# GENET register map
File version: 5
BCM2711 GENET v5 Ethernet controller
Registers are read-write, no defined reset value unless marked. A register's access mark holds for its fields unless they carry their own. Offsets are from the block's base; lines under a group give offsets from that group; [hi:lo] are bit positions; {n}, {i} and the like mark numbered series; 'fields as' and 'values as' point back to an identical list; <NAME> marks a mode.

## Memory map
0x00000000 GENET size 0x10000

## GENET
Base 0x00000000
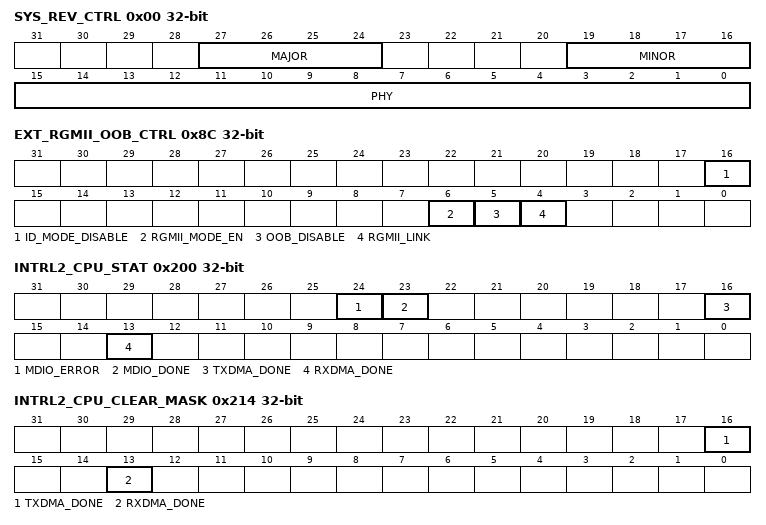
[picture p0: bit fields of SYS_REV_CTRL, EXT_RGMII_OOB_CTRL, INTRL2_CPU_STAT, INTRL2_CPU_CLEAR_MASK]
0x00 SYS_REV_CTRL ro — GENET_SYS_REV_CTRL (if_genetreg.h:38): the controller's revision; FreeBSD attaches major 6 only (if_genet.c:264-272)
  [27:24] MAJOR — Major revision, 6 for GENET v5 (if_genetreg.h:39, 41-43)
  [19:16] MINOR — Minor revision (if_genetreg.h:40, 44)
  [15:0] PHY — Internal PHY revision (if_genetreg.h:46)
0x04 SYS_PORT_CTRL — GENET_SYS_PORT_CTRL (if_genetreg.h:47)
  [31:0] MODE — Written whole: 3 for an external gigabit PHY over RGMII, 0 otherwise (if_genetreg.h:48; if_genet.c:915-925)
0x08 SYS_RBUF_FLUSH_CTRL — GENET_SYS_RBUF_FLUSH_CTRL (if_genetreg.h:49): FreeBSD pulses RESET and writes 0 (if_genet.c:492-501), and trusts UMAC_MAC0/1 only while it reads 0 (if_genet.c:465-468)
  [1] RESET — Flush the receive buffer (if_genetreg.h:50)
0x8C EXT_RGMII_OOB_CTRL — GENET_EXT_RGMII_OOB_CTRL (if_genetreg.h:52): set on link up (if_genet.c:1767-1775)
  [16] ID_MODE_DISABLE — Disable the MAC's internal delay (if_genetreg.h:53)
  [6] RGMII_MODE_EN — Enable RGMII (if_genetreg.h:54)
  [5] OOB_DISABLE — Disable out-of-band status (if_genetreg.h:55)
  [4] RGMII_LINK — The link is up (if_genetreg.h:56)
0x200 INTRL2_CPU_STAT ro — GENET_INTRL2_CPU_STAT (if_genetreg.h:57): pending interrupts, masked or not (if_genet.c:1354-1355)
  [24] MDIO_ERROR — An MDIO command failed (if_genetreg.h:62)
  [23] MDIO_DONE — An MDIO command finished (if_genetreg.h:63)
  [16] TXDMA_DONE — A transmit descriptor was sent (if_genetreg.h:64)
  [13] RXDMA_DONE — A receive descriptor was filled (if_genetreg.h:65)
0x208 INTRL2_CPU_CLEAR wo — GENET_INTRL2_CPU_CLEAR (if_genetreg.h:58): a 1 bit clears that pending interrupt (if_genet.c:1356)
  [31:0] IRQS — One bit per interrupt, STAT's bits
0x20C INTRL2_CPU_STAT_MASK ro — GENET_INTRL2_CPU_STAT_MASK (if_genetreg.h:59): the masked interrupts (if_genet.c:1355)
  [31:0] IRQS — One bit per interrupt, STAT's bits
0x210 INTRL2_CPU_SET_MASK wo — GENET_INTRL2_CPU_SET_MASK (if_genetreg.h:60): a 1 bit masks that interrupt; unverified, since FreeBSD writes all ones here and then to CLEAR_MASK to disable them (if_genet.c:544-545)
  [31:0] IRQS — One bit per interrupt, STAT's bits
0x214 INTRL2_CPU_CLEAR_MASK wo — GENET_INTRL2_CPU_CLEAR_MASK (if_genetreg.h:61): a 1 bit unmasks that interrupt (if_genet.c:536-537, 713-714); unverified, see SET_MASK. Its two named fields are the interrupts erx_genet unmasks, each one write
  [16] TXDMA_DONE write-1-clears — Unmasks STAT's TXDMA_DONE
  [13] RXDMA_DONE write-1-clears — Unmasks STAT's RXDMA_DONE
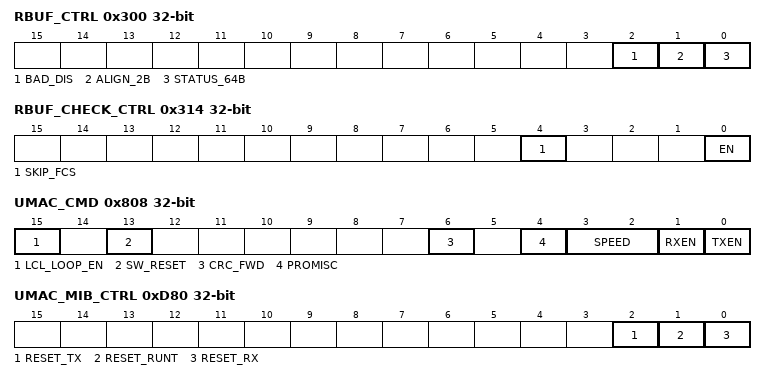
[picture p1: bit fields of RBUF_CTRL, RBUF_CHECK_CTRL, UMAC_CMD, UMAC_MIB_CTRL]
0x300 RBUF_CTRL — GENET_RBUF_CTRL (if_genetreg.h:66)
  [2] BAD_DIS — if_genetreg.h:67; FreeBSD never sets it
  [1] ALIGN_2B — Write two bytes of padding before each frame (if_genetreg.h:68; if_genet.c:522-524)
  [0] STATUS_64B — Prepend a 64-byte status block to each received frame (if_genetreg.h:69; if_genet.c:572-582)
0x314 RBUF_CHECK_CTRL — GENET_RBUF_CHECK_CTRL (if_genetreg.h:70)
  [4] SKIP_FCS — if_genetreg.h:72; FreeBSD never sets it
  [0] EN — Check received checksums (if_genetreg.h:71; if_genet.c:572-581)
0x3B4 RBUF_TBUF_SIZE_CTRL — GENET_RBUF_TBUF_SIZE_CTRL (if_genetreg.h:73)
  [31:0] SIZE — Written whole; FreeBSD writes 1 (if_genet.c:526)
0x600 TBUF_CTRL — GENET_TBUF_CTRL (if_genetreg.h:74)
  [0] STATUS_64B — Each frame sent starts with a 64-byte status block; FreeBSD sets it with GENET_RBUF_64B_EN's bit (if_genet.c:584-590)
0x808 UMAC_CMD — GENET_UMAC_CMD (if_genetreg.h:75)
  [15] LCL_LOOP_EN — Local loopback, set with SW_RESET (if_genetreg.h:76)
  [13] SW_RESET — Hold the MAC in reset (if_genetreg.h:77; if_genet.c:504-508)
  [6] CRC_FWD — Keep the received CRC in the frame (if_genetreg.h:89)
  [4] PROMISC — Take every frame, bypassing the address filter (if_genetreg.h:78)
  [3:2] SPEED — 0 for 10, 1 for 100, 2 for 1000 Mbit/s (if_genetreg.h:80-83)
  [1] RXEN — Enable the receiver (if_genetreg.h:91)
  [0] TXEN — Enable the transmitter (if_genetreg.h:92)
0x80C UMAC_MAC0 — GENET_UMAC_MAC0 (if_genetreg.h:93)
  [31:0] ADDR — Bytes 0 to 3 of the station address, byte 0 in bits 31:24 (if_genet.c:1029-1031)
0x810 UMAC_MAC1 — GENET_UMAC_MAC1 (if_genetreg.h:94)
  [15:0] ADDR — Bytes 4 and 5 of the station address, byte 4 in bits 15:8 (if_genet.c:468, 1032-1033)
0x814 UMAC_MAX_FRAME_LEN — GENET_UMAC_MAX_FRAME_LEN (if_genetreg.h:95)
  [31:0] LENGTH — Written whole; FreeBSD writes 1536 (if_genet.c:520)
0xD80 UMAC_MIB_CTRL — GENET_UMAC_MIB_CTRL (if_genetreg.h:97): FreeBSD sets the three resets and writes 0 (if_genet.c:510-512)
  [2] RESET_TX — Clear the transmit counters (if_genetreg.h:98)
  [1] RESET_RUNT — Clear the runt counter (if_genetreg.h:99)
  [0] RESET_RX — Clear the receive counters (if_genetreg.h:100)
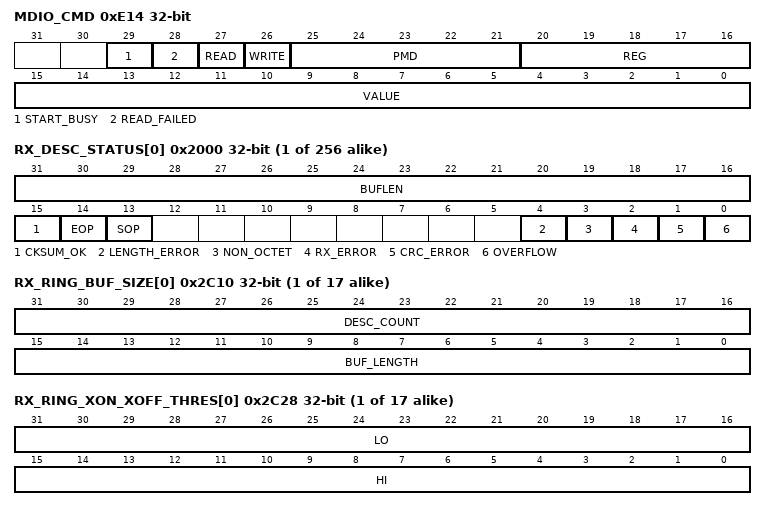
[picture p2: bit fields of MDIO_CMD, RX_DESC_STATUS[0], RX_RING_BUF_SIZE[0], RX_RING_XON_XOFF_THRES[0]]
0xE14 MDIO_CMD — GENET_MDIO_CMD (if_genetreg.h:101): one clause 22 command; FreeBSD polls START_BUSY 1000 times 10 us apart (if_genet.c:1680-1711)
  [29] START_BUSY — Start the command; reads 1 until it finishes (if_genetreg.h:102)
  [28] READ_FAILED ro — The PHY did not answer the read (if_genetreg.h:103)
  [27] READ — A read (if_genetreg.h:104)
  [26] WRITE — A write (if_genetreg.h:105)
  [25:21] PMD — PHY address (if_genetreg.h:106, 108)
  [20:16] REG — PHY register (if_genetreg.h:107, 109)
  [15:0] VALUE — The register value written or read (if_genetreg.h:110)
0xE50 UMAC_MDF_CTRL — GENET_UMAC_MDF_CTRL (if_genetreg.h:111)
  [16:0] ENABLE — One bit per address filter; FreeBSD enables filter n with bit 16 - n (if_genetreg.h:114; if_genet.c:1006-1012)
{0xE54+8i} UMAC_MDF_ADDR0[{i}] (i=0..16) — GENET_UMAC_MDF_ADDR0 (if_genetreg.h:112): filter n's first two address bytes
  [15:0] ADDR — Byte 0 in bits 15:8, byte 1 in bits 7:0 (if_genet.c:958)
{0xE58+8i} UMAC_MDF_ADDR1[{i}] (i=0..16) — GENET_UMAC_MDF_ADDR1 (if_genetreg.h:113): filter n's last four address bytes
  [31:0] ADDR — Byte 2 in bits 31:24 to byte 5 in bits 7:0 (if_genet.c:959)
{0x2000+0xC*i} RX_DESC_STATUS[{i}] (i=0..255) — GENET_RX_DESC_STATUS (if_genetreg.h:168): descriptor i's length and flags, at 12 * i
  [31:16] BUFLEN — Bytes written, the two bytes of padding before the frame and, with RBUF_CTRL.STATUS_64B, the 64-byte status block included (if_genetreg.h:169-171; if_genet.c:1435-1441). FreeBSD masks 12 bits, 27:16; the field takes all 16, as the other published driver does (docs/research-genet-bcm2711.md, "The receive status word") and docs/design-device-dma.md reads it, so a set high bit breaks the queue rather than shortening a length
  [15] CKSUM_OK — if_genetreg.h:172-173 name bit 15 both OWN, marked unsure, and CKSUM_OK; unverified
  [14] EOP — End of packet (if_genetreg.h:174)
  [13] SOP — Start of packet (if_genetreg.h:175)
  [4] LENGTH_ERROR — The frame was oversize or its length wrong (docs/research-genet-bcm2711.md, "The receive status word")
  [3] NON_OCTET — The frame was not a whole number of octets (docs/research-genet-bcm2711.md, "The receive status word")
  [2] RX_ERROR — The frame was received in error (if_genetreg.h:176)
  [1] CRC_ERROR — The frame failed its CRC (docs/research-genet-bcm2711.md, "The receive status word")
  [0] OVERFLOW — The receive buffer overflowed (docs/research-genet-bcm2711.md, "The receive status word")
{0x2004+0xC*i} RX_DESC_ADDR_LO[{i}] (i=0..255) — GENET_RX_DESC_ADDRESS_LO (if_genetreg.h:177): bits 31:0 of descriptor i's buffer's bus address
  [31:0] ADDR — Low address bits
{0x2008+0xC*i} RX_DESC_ADDR_HI[{i}] (i=0..255) — GENET_RX_DESC_ADDRESS_HI (if_genetreg.h:178): bits 63:32 of the address; DMA reaches 40 bits (if_genet.c:618)
  [31:0] ADDR — High address bits
{0x2C00+0x40*i} RX_RING_WRITE_PTR_LO[{i}] (i=0..16) — GENET_RX_DMA_WRITE_PTR_LO (if_genetreg.h:127)
  [31:0] WORD — A word index into the direction's descriptor registers, not a memory address: FreeBSD sets the end to 256 * 12 / 4 - 1 and the others to 0 (if_genet.c:740-755, 786-801)
{0x2C04+0x40*i} RX_RING_WRITE_PTR_HI[{i}] (i=0..16) — GENET_RX_DMA_WRITE_PTR_HI (if_genetreg.h:128)
  fields as RX_RING_WRITE_PTR_LO[0]
{0x2C08+0x40*i} RX_RING_PROD_INDEX[{i}] (i=0..16) — GENET_RX_DMA_PROD_INDEX (if_genetreg.h:129): the controller advances it per filled descriptor
  [15:0] INDEX — Free-running producer index, masked 0xffff (if_genetreg.h:131)
{0x2C0C+0x40*i} RX_RING_CONS_INDEX[{i}] (i=0..16) — GENET_RX_DMA_CONS_INDEX (if_genetreg.h:130): the driver advances it per descriptor taken
  [15:0] INDEX — Free-running consumer index, masked 0xffff (if_genetreg.h:131)
{0x2C10+0x40*i} RX_RING_BUF_SIZE[{i}] (i=0..16) — GENET_RX_DMA_RING_BUF_SIZE (if_genetreg.h:132)
  [31:16] DESC_COUNT — Descriptors in the ring (if_genetreg.h:133)
  [15:0] BUF_LENGTH — Bytes of each buffer (if_genetreg.h:134; FreeBSD writes MCLBYTES, 2048)
{0x2C14+0x40*i} RX_RING_START_ADDR_LO[{i}] (i=0..16) — GENET_RX_DMA_START_ADDR_LO (if_genetreg.h:137)
  fields as RX_RING_WRITE_PTR_LO[0]
{0x2C18+0x40*i} RX_RING_START_ADDR_HI[{i}] (i=0..16) — GENET_RX_DMA_START_ADDR_HI (if_genetreg.h:138)
  fields as RX_RING_WRITE_PTR_LO[0]
{0x2C1C+0x40*i} RX_RING_END_ADDR_LO[{i}] (i=0..16) — GENET_RX_DMA_END_ADDR_LO (if_genetreg.h:139)
  fields as RX_RING_WRITE_PTR_LO[0]
{0x2C20+0x40*i} RX_RING_END_ADDR_HI[{i}] (i=0..16) — GENET_RX_DMA_END_ADDR_HI (if_genetreg.h:140)
  fields as RX_RING_WRITE_PTR_LO[0]
{0x2C28+0x40*i} RX_RING_XON_XOFF_THRES[{i}] (i=0..16) — GENET_RX_DMA_XON_XOFF_THRES (if_genetreg.h:141); FreeBSD writes 5 and 256 / 16 (if_genet.c:798-799)
  [31:16] LO — The low threshold (if_genetreg.h:142, 144)
  [15:0] HI — The high threshold (if_genetreg.h:143); which of XON and XOFF it is, FreeBSD does not say
{0x2C2C+0x40*i} RX_RING_READ_PTR_LO[{i}] (i=0..16) — GENET_RX_DMA_READ_PTR_LO (if_genetreg.h:145)
  fields as RX_RING_WRITE_PTR_LO[0]
{0x2C30+0x40*i} RX_RING_READ_PTR_HI[{i}] (i=0..16) — GENET_RX_DMA_READ_PTR_HI (if_genetreg.h:146)
  fields as RX_RING_WRITE_PTR_LO[0]
0x3040 RX_DMA_RING_CFG — GENET_RX_DMA_RING_CFG (if_genetreg.h:209)
  [16:0] ENABLE — One bit per ring, ring q at bit q (if_genet.c:803)
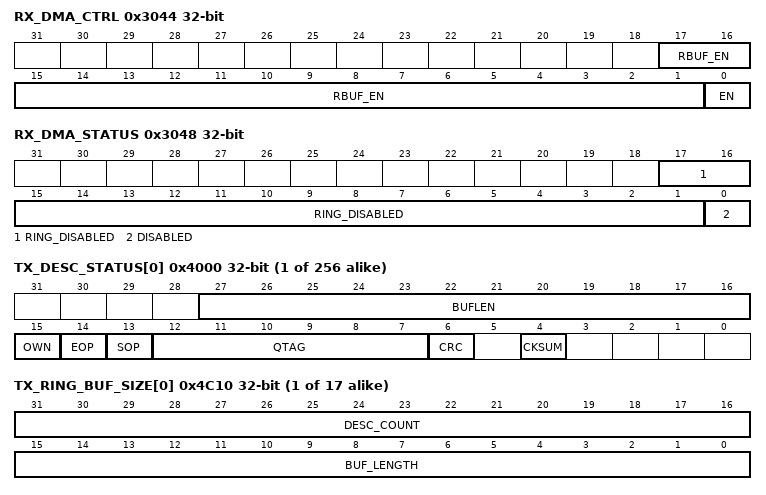
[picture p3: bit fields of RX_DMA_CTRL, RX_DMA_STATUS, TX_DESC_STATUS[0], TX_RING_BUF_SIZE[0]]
0x3044 RX_DMA_CTRL — GENET_RX_DMA_CTRL (if_genetreg.h:210)
  [17:1] RBUF_EN — One bit per ring, ring q at bit q + 1 (if_genetreg.h:211)
  [0] EN — Run the receive engine (if_genetreg.h:212)
0x3048 RX_DMA_STATUS ro — The receive DMA block's status, block offset 0x1048, which if_genetreg.h does not name (docs/research-genet-bcm2711.md, "The DMA status register"): its bits mirror RX_DMA_CTRL's, each set once that part has stopped
  [17:1] RING_DISABLED — One bit per ring, ring q at bit q + 1, set once ring q has stopped; inferred from the poll the facts record describes, which the board pass settles
  [0] DISABLED — The block's DMA has stopped (the facts record, "The DMA status register")
0x304C RX_SCB_BURST_SIZE — GENET_RX_SCB_BURST_SIZE (if_genetreg.h:213)
  [31:0] SIZE — Written whole; FreeBSD writes 8 (if_genet.c:784)
{0x4000+0xC*i} TX_DESC_STATUS[{i}] (i=0..255) — GENET_TX_DESC_STATUS (if_genetreg.h:180): descriptor i's length and flags, at 12 * i
  [27:16] BUFLEN — Bytes to send: __BITS(27,16) at if_genetreg.h:181, though the mask at :189 is 0x7ff0000, bits 26:16; unverified which
  [15] OWN — Owned by the controller (if_genetreg.h:182)
  [14] EOP — End of packet (if_genetreg.h:183)
  [13] SOP — Start of packet (if_genetreg.h:184)
  [12:7] QTAG — Queue tag, mask 0x1f80 (if_genetreg.h:185, 190)
  [6] CRC — Append the Ethernet CRC (if_genetreg.h:186)
  [4] CKSUM — Insert the checksum the status block describes (if_genetreg.h:187)
{0x4004+0xC*i} TX_DESC_ADDR_LO[{i}] (i=0..255) — GENET_TX_DESC_ADDRESS_LO (if_genetreg.h:191): bits 31:0 of descriptor i's buffer's bus address
  [31:0] ADDR — Low address bits
{0x4008+0xC*i} TX_DESC_ADDR_HI[{i}] (i=0..255) — GENET_TX_DESC_ADDRESS_HI (if_genetreg.h:192): bits 63:32 of the address; DMA reaches 40 bits (if_genet.c:618)
  [31:0] ADDR — High address bits
{0x4C00+0x40*i} TX_RING_READ_PTR_LO[{i}] (i=0..16) — GENET_TX_DMA_READ_PTR_LO (if_genetreg.h:149)
  fields as RX_RING_WRITE_PTR_LO[0]
{0x4C04+0x40*i} TX_RING_READ_PTR_HI[{i}] (i=0..16) — GENET_TX_DMA_READ_PTR_HI (if_genetreg.h:150)
  fields as RX_RING_WRITE_PTR_LO[0]
{0x4C08+0x40*i} TX_RING_CONS_INDEX[{i}] (i=0..16) — GENET_TX_DMA_CONS_INDEX (if_genetreg.h:151): the controller advances it per descriptor sent
  [15:0] INDEX — Free-running consumer index, masked 0xffff (if_genetreg.h:153)
{0x4C0C+0x40*i} TX_RING_PROD_INDEX[{i}] (i=0..16) — GENET_TX_DMA_PROD_INDEX (if_genetreg.h:152): the driver advances it per descriptor posted (if_genet.c:1228)
  [15:0] INDEX — Free-running producer index, masked 0xffff (if_genetreg.h:153)
{0x4C10+0x40*i} TX_RING_BUF_SIZE[{i}] (i=0..16) — GENET_TX_DMA_RING_BUF_SIZE (if_genetreg.h:154)
  [31:16] DESC_COUNT — Descriptors in the ring (if_genetreg.h:155)
  [15:0] BUF_LENGTH — Bytes of each buffer (if_genetreg.h:156; FreeBSD writes MCLBYTES, 2048)
{0x4C14+0x40*i} TX_RING_START_ADDR_LO[{i}] (i=0..16) — GENET_TX_DMA_START_ADDR_LO (if_genetreg.h:159)
  fields as RX_RING_WRITE_PTR_LO[0]
{0x4C18+0x40*i} TX_RING_START_ADDR_HI[{i}] (i=0..16) — GENET_TX_DMA_START_ADDR_HI (if_genetreg.h:160)
  fields as RX_RING_WRITE_PTR_LO[0]
{0x4C1C+0x40*i} TX_RING_END_ADDR_LO[{i}] (i=0..16) — GENET_TX_DMA_END_ADDR_LO (if_genetreg.h:161)
  fields as RX_RING_WRITE_PTR_LO[0]
{0x4C20+0x40*i} TX_RING_END_ADDR_HI[{i}] (i=0..16) — GENET_TX_DMA_END_ADDR_HI (if_genetreg.h:162)
  fields as RX_RING_WRITE_PTR_LO[0]
{0x4C24+0x40*i} TX_RING_MBUF_DONE_THRES[{i}] (i=0..16) — GENET_TX_DMA_MBUF_DONE_THRES (if_genetreg.h:163); FreeBSD writes 1 (if_genet.c:752)
  [31:0] WORD — The threshold, written whole
{0x4C28+0x40*i} TX_RING_FLOW_PERIOD[{i}] (i=0..16) — GENET_TX_DMA_FLOW_PERIOD (if_genetreg.h:164); FreeBSD writes 0 (if_genet.c:753)
  [31:0] WORD — The period, written whole
{0x4C2C+0x40*i} TX_RING_WRITE_PTR_LO[{i}] (i=0..16) — GENET_TX_DMA_WRITE_PTR_LO (if_genetreg.h:165)
  fields as RX_RING_WRITE_PTR_LO[0]
{0x4C30+0x40*i} TX_RING_WRITE_PTR_HI[{i}] (i=0..16) — GENET_TX_DMA_WRITE_PTR_HI (if_genetreg.h:166)
  fields as RX_RING_WRITE_PTR_LO[0]
0x5040 TX_DMA_RING_CFG — GENET_TX_DMA_RING_CFG (if_genetreg.h:215)
  [16:0] ENABLE — One bit per ring, ring q at bit q (if_genet.c:757)
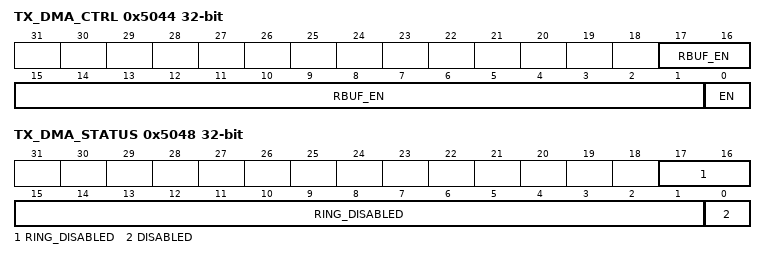
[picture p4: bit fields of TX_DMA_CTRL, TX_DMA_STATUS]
0x5044 TX_DMA_CTRL — GENET_TX_DMA_CTRL (if_genetreg.h:216)
  [17:1] RBUF_EN — One bit per ring, ring q at bit q + 1 (if_genetreg.h:217)
  [0] EN — Run the transmit engine (if_genetreg.h:218)
0x5048 TX_DMA_STATUS ro — The transmit DMA block's status, block offset 0x1048, which if_genetreg.h does not name (docs/research-genet-bcm2711.md, "The DMA status register"): its bits mirror TX_DMA_CTRL's, each set once that part has stopped
  fields as RX_DMA_STATUS
0x504C TX_SCB_BURST_SIZE — GENET_TX_SCB_BURST_SIZE (if_genetreg.h:219)
  [31:0] SIZE — Written whole; FreeBSD writes 8 (if_genet.c:738)

## Notices in the file
Copyright (c) 2026, Stanislav Sedov <stas@deglitch.com>
SPDX-License-Identifier: BSD-2-Clause
